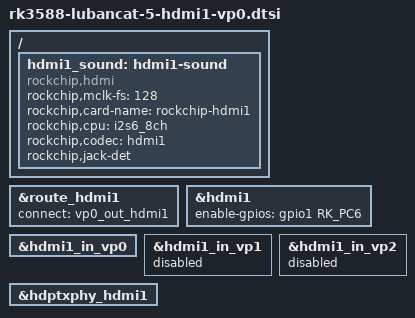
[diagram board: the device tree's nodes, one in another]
#include <dt-bindings/gpio/gpio.h>
#include "rk3588.dtsi"

/ {
	hdmi1_sound: hdmi1-sound {
		status = "okay";
		compatible = "rockchip,hdmi";
		rockchip,mclk-fs = <128>;
		rockchip,card-name = "rockchip-hdmi1";
		rockchip,cpu = <&i2s6_8ch>;
		rockchip,codec = <&hdmi1>;
		rockchip,jack-det;
	};
};

&route_hdmi1{
	status = "okay";
	connect = <&vp0_out_hdmi1>;
};

&hdmi1 {
	enable-gpios = <&gpio1 RK_PC6 GPIO_ACTIVE_HIGH>;
	status = "okay";
};

&hdmi1_in_vp0 {
	status = "okay";
};

&hdmi1_in_vp1 {
	status = "disabled";
};

&hdmi1_in_vp2 {
	status = "disabled";
};

&hdptxphy_hdmi1 {
	status = "okay";
};
